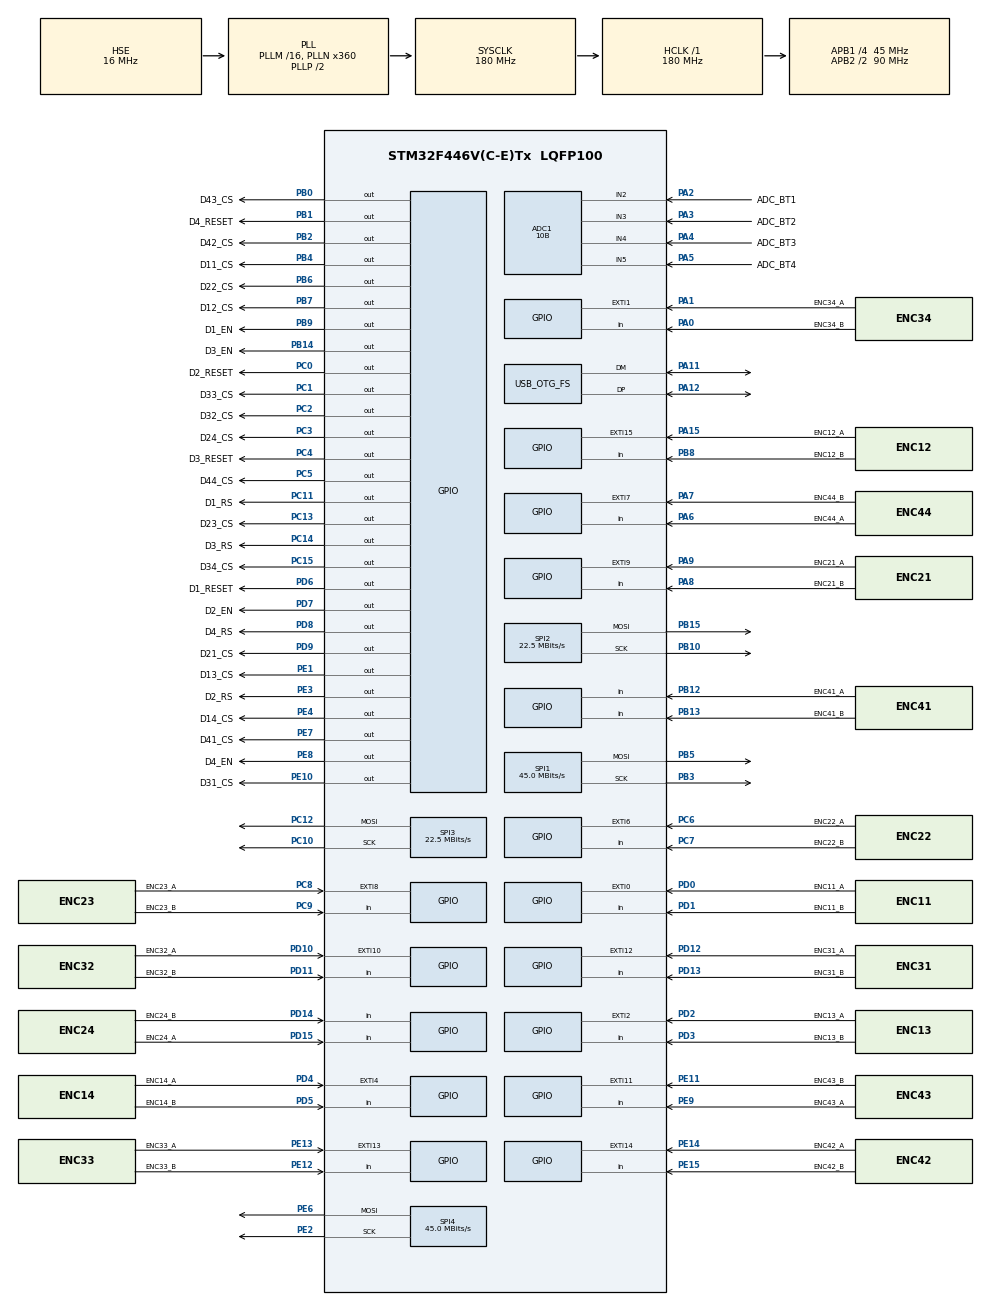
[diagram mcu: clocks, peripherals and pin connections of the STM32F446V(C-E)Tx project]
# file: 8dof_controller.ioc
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ADC1.Channel-2\#ChannelRegularConversion=ADC_CHANNEL_2
ADC1.Channel-6\#ChannelRegularConversion=ADC_CHANNEL_3
ADC1.Channel-7\#ChannelRegularConversion=ADC_CHANNEL_4
ADC1.Channel-8\#ChannelRegularConversion=ADC_CHANNEL_5
ADC1.ClockPrescaler=ADC_CLOCK_SYNC_PCLK_DIV4
ADC1.ContinuousConvMode=DISABLE
ADC1.DMAContinuousRequests=DISABLE
ADC1.DiscontinuousConvMode=DISABLE
ADC1.EOCSelection=ADC_EOC_SEQ_CONV
ADC1.ExternalTrigConv=ADC_SOFTWARE_START
ADC1.NbrOfConversion=4
ADC1.NbrOfConversionFlag=1
ADC1.Rank-2\#ChannelRegularConversion=1
ADC1.Rank-6\#ChannelRegularConversion=2
ADC1.Rank-7\#ChannelRegularConversion=3
ADC1.Rank-8\#ChannelRegularConversion=4
ADC1.Resolution=ADC_RESOLUTION_10B
ADC1.SamplingTime-2\#ChannelRegularConversion=ADC_SAMPLETIME_3CYCLES
ADC1.SamplingTime-6\#ChannelRegularConversion=ADC_SAMPLETIME_3CYCLES
ADC1.SamplingTime-7\#ChannelRegularConversion=ADC_SAMPLETIME_3CYCLES
ADC1.SamplingTime-8\#ChannelRegularConversion=ADC_SAMPLETIME_3CYCLES
ADC1.master=1
AL94.I-CUBE-USBD-COMPOSITE.1.0.3.CompositeCcUSBJjCOMPOSITEJjCDCIiACM=true
AL94.I-CUBE-USBD-COMPOSITE.1.0.3.CompositeCcUSBJjCOMPOSITEJjCOMPOSITE=true
AL94.I-CUBE-USBD-COMPOSITE.1.0.3.CompositeCcUSBJjCOMPOSITEJjCore=true
AL94.I-CUBE-USBD-COMPOSITE.1.0.3.CompositeCcUSBJjCOMPOSITEJjHIDIiCUSTOM=true
AL94.I-CUBE-USBD-COMPOSITE.1.0.3._USBD_USE_CDC_ACM=true
AL94.I-CUBE-USBD-COMPOSITE.1.0.3._USBD_USE_HID_CUSTOM=true
AL94.I-CUBE-USBD-COMPOSITE.1.0.3._USBD_USE_UAC_SPKR=false
Dma.ADC1.4.Direction=DMA_PERIPH_TO_MEMORY
Dma.ADC1.4.FIFOMode=DMA_FIFOMODE_DISABLE
Dma.ADC1.4.Instance=DMA2_Stream0
Dma.ADC1.4.MemDataAlignment=DMA_MDATAALIGN_WORD
Dma.ADC1.4.MemInc=DMA_MINC_ENABLE
Dma.ADC1.4.Mode=DMA_CIRCULAR
Dma.ADC1.4.PeriphDataAlignment=DMA_PDATAALIGN_WORD
Dma.ADC1.4.PeriphInc=DMA_PINC_DISABLE
Dma.ADC1.4.Priority=DMA_PRIORITY_LOW
Dma.Request0=SPI2_TX
Dma.Request1=SPI3_TX
Dma.Request2=SPI1_TX
Dma.Request3=SPI4_TX
Dma.Request4=ADC1
Dma.SPI1_TX.2.Direction=DMA_MEMORY_TO_PERIPH
Dma.SPI1_TX.2.FIFOMode=DMA_FIFOMODE_DISABLE
Dma.SPI1_TX.2.Instance=DMA2_Stream3
Dma.SPI1_TX.2.MemDataAlignment=DMA_MDATAALIGN_HALFWORD
Dma.SPI1_TX.2.MemInc=DMA_MINC_ENABLE
Dma.SPI1_TX.2.Mode=DMA_NORMAL
Dma.SPI1_TX.2.PeriphDataAlignment=DMA_PDATAALIGN_HALFWORD
Dma.SPI1_TX.2.PeriphInc=DMA_PINC_DISABLE
Dma.SPI1_TX.2.Priority=DMA_PRIORITY_HIGH
Dma.SPI2_TX.0.Direction=DMA_MEMORY_TO_PERIPH
Dma.SPI2_TX.0.FIFOMode=DMA_FIFOMODE_DISABLE
Dma.SPI2_TX.0.Instance=DMA1_Stream4
Dma.SPI2_TX.0.MemDataAlignment=DMA_MDATAALIGN_HALFWORD
Dma.SPI2_TX.0.MemInc=DMA_MINC_ENABLE
Dma.SPI2_TX.0.Mode=DMA_NORMAL
Dma.SPI2_TX.0.PeriphDataAlignment=DMA_PDATAALIGN_HALFWORD
Dma.SPI2_TX.0.PeriphInc=DMA_PINC_DISABLE
Dma.SPI2_TX.0.Priority=DMA_PRIORITY_HIGH
Dma.SPI3_TX.1.Direction=DMA_MEMORY_TO_PERIPH
Dma.SPI3_TX.1.FIFOMode=DMA_FIFOMODE_DISABLE
Dma.SPI3_TX.1.Instance=DMA1_Stream5
Dma.SPI3_TX.1.MemDataAlignment=DMA_MDATAALIGN_HALFWORD
Dma.SPI3_TX.1.MemInc=DMA_MINC_ENABLE
Dma.SPI3_TX.1.Mode=DMA_NORMAL
Dma.SPI3_TX.1.PeriphDataAlignment=DMA_PDATAALIGN_HALFWORD
Dma.SPI3_TX.1.PeriphInc=DMA_PINC_DISABLE
Dma.SPI3_TX.1.Priority=DMA_PRIORITY_HIGH
Dma.SPI4_TX.3.Direction=DMA_MEMORY_TO_PERIPH
Dma.SPI4_TX.3.FIFOMode=DMA_FIFOMODE_DISABLE
Dma.SPI4_TX.3.Instance=DMA2_Stream1
Dma.SPI4_TX.3.MemDataAlignment=DMA_MDATAALIGN_HALFWORD
Dma.SPI4_TX.3.MemInc=DMA_MINC_ENABLE
Dma.SPI4_TX.3.Mode=DMA_NORMAL
Dma.SPI4_TX.3.PeriphDataAlignment=DMA_PDATAALIGN_HALFWORD
Dma.SPI4_TX.3.PeriphInc=DMA_PINC_DISABLE
Dma.SPI4_TX.3.Priority=DMA_PRIORITY_HIGH
FREERTOS.Tasks01=defaultTask,0,128,StartDefaultTask,Default,NULL,Dynamic,NULL,NULL
FREERTOS.configTOTAL_HEAP_SIZE=24000
FREERTOS.configUSE_NEWLIB_REENTRANT=1
Mcu.Family=STM32F4
Mcu.Name=STM32F446V(C-E)Tx
Mcu.Package=LQFP100
NVIC.DMA1_Stream4_IRQn=true\:5\:0\:false\:false\:true\:true\:false\:true\:true
NVIC.DMA1_Stream5_IRQn=true\:5\:0\:false\:false\:true\:true\:false\:true\:true
NVIC.DMA2_Stream0_IRQn=true\:5\:0\:false\:false\:true\:true\:false\:true\:true
NVIC.DMA2_Stream1_IRQn=true\:5\:0\:false\:false\:true\:true\:false\:true\:true
NVIC.DMA2_Stream3_IRQn=true\:5\:0\:false\:false\:true\:true\:false\:true\:true
NVIC.EXTI0_IRQn=true\:5\:0\:false\:false\:true\:true\:true\:true\:true
NVIC.EXTI15_10_IRQn=true\:5\:0\:false\:false\:true\:true\:true\:true\:true
NVIC.EXTI1_IRQn=true\:5\:0\:false\:false\:true\:true\:true\:true\:true
NVIC.EXTI2_IRQn=true\:5\:0\:false\:false\:true\:true\:true\:true\:true
NVIC.EXTI4_IRQn=true\:5\:0\:false\:false\:true\:true\:true\:true\:true
NVIC.EXTI9_5_IRQn=true\:5\:0\:false\:false\:true\:true\:true\:true\:true
NVIC.OTG_FS_IRQn=true\:5\:0\:false\:false\:true\:true\:true\:true\:true
NVIC.PriorityGroup=NVIC_PRIORITYGROUP_4
NVIC.SPI1_IRQn=true\:5\:0\:false\:false\:true\:true\:true\:true\:true
NVIC.SPI2_IRQn=true\:5\:0\:false\:false\:true\:true\:true\:true\:true
NVIC.SPI3_IRQn=true\:5\:0\:false\:false\:true\:true\:true\:true\:true
NVIC.SPI4_IRQn=true\:5\:0\:false\:false\:true\:true\:true\:true\:true
NVIC.TIM2_IRQn=true\:15\:0\:false\:false\:true\:false\:false\:true\:true
NVIC.TIM3_IRQn=true\:5\:0\:false\:false\:true\:true\:true\:true\:true
NVIC.TIM6_DAC_IRQn=true\:5\:0\:false\:false\:true\:true\:true\:true\:true
NVIC.TimeBase=TIM2_IRQn
NVIC.TimeBaseIP=TIM2
PA0-WKUP.GPIO_Label=ENC34_B
PA0-WKUP.Signal=GPIO_Input
PA1.GPIO_Label=ENC34_A
PA1.GPIO_ModeDefaultEXTI=GPIO_MODE_IT_RISING_FALLING
PA1.Signal=GPXTI1
PA11.Mode=Device_Only
PA11.Signal=USB_OTG_FS_DM
PA12.Mode=Device_Only
PA12.Signal=USB_OTG_FS_DP
PA13.Mode=Serial_Wire
PA13.Signal=SYS_JTMS-SWDIO
PA14.Mode=Serial_Wire
PA14.Signal=SYS_JTCK-SWCLK
PA15.GPIO_Label=ENC12_A
PA15.GPIO_ModeDefaultEXTI=GPIO_MODE_IT_RISING_FALLING
PA15.Signal=GPXTI15
PA2.GPIO_Label=ADC_BT1
PA2.Signal=ADCx_IN2
PA3.GPIO_Label=ADC_BT2
PA3.Signal=ADCx_IN3
PA4.GPIO_Label=ADC_BT3
PA4.Signal=ADCx_IN4
PA5.GPIO_Label=ADC_BT4
PA5.Signal=ADCx_IN5
PA6.GPIO_Label=ENC44_A
PA6.Signal=GPIO_Input
PA7.GPIO_Label=ENC44_B
PA7.GPIO_ModeDefaultEXTI=GPIO_MODE_IT_RISING_FALLING
PA7.Signal=GPXTI7
PA8.GPIO_Label=ENC21_B
PA8.Signal=GPIO_Input
PA9.GPIO_Label=ENC21_A
PA9.GPIO_ModeDefaultEXTI=GPIO_MODE_IT_RISING_FALLING
PA9.Signal=GPXTI9
PB0.GPIO_Label=D43_CS
PB0.GPIO_Speed=GPIO_SPEED_FREQ_VERY_HIGH
PB0.PinState=GPIO_PIN_SET
PB0.Signal=GPIO_Output
PB1.GPIO_Label=D4_RESET
PB1.GPIO_PuPd=GPIO_PULLUP
PB1.PinState=GPIO_PIN_SET
PB1.Signal=GPIO_Output
PB10.GPIO_PuPd=GPIO_PULLDOWN
PB10.Mode=TX_Only_Simplex_Unidirect_Master
PB10.Signal=SPI2_SCK
PB12.GPIO_Label=ENC41_A
PB12.Signal=GPIO_Input
PB13.GPIO_Label=ENC41_B
PB13.Signal=GPIO_Input
PB14.GPIO_Label=D3_EN
PB14.PinState=GPIO_PIN_RESET
PB14.Signal=GPIO_Output
PB15.GPIO_PuPd=GPIO_PULLUP
PB15.Mode=TX_Only_Simplex_Unidirect_Master
PB15.Signal=SPI2_MOSI
PB2.GPIO_Label=D42_CS
PB2.PinState=GPIO_PIN_SET
PB2.Signal=GPIO_Output
PB3.GPIO_PuPd=GPIO_PULLDOWN
PB3.Mode=TX_Only_Simplex_Unidirect_Master
PB3.Signal=SPI1_SCK
PB4.GPIO_Label=D11_CS
PB4.GPIO_Speed=GPIO_SPEED_FREQ_VERY_HIGH
PB4.PinState=GPIO_PIN_SET
PB4.Signal=GPIO_Output
PB5.GPIO_PuPd=GPIO_PULLUP
PB5.Mode=TX_Only_Simplex_Unidirect_Master
PB5.Signal=SPI1_MOSI
PB6.GPIO_Label=D22_CS
PB6.GPIO_Speed=GPIO_SPEED_FREQ_VERY_HIGH
PB6.PinState=GPIO_PIN_SET
PB6.Signal=GPIO_Output
PB7.GPIO_Label=D12_CS
PB7.GPIO_Speed=GPIO_SPEED_FREQ_VERY_HIGH
PB7.PinState=GPIO_PIN_SET
PB7.Signal=GPIO_Output
PB8.GPIO_Label=ENC12_B
PB8.Signal=GPIO_Input
PB9.GPIO_Label=D1_EN
PB9.GPIO_PuPd=GPIO_NOPULL
PB9.PinState=GPIO_PIN_RESET
PB9.Signal=GPIO_Output
PC0.GPIO_Label=D2_RESET
PC0.GPIO_PuPd=GPIO_PULLUP
PC0.PinState=GPIO_PIN_SET
PC0.Signal=GPIO_Output
PC1.GPIO_Label=D33_CS
PC1.GPIO_Speed=GPIO_SPEED_FREQ_VERY_HIGH
PC1.PinState=GPIO_PIN_SET
PC1.Signal=GPIO_Output
PC10.GPIO_PuPd=GPIO_PULLDOWN
PC10.Mode=TX_Only_Simplex_Unidirect_Master
PC10.Signal=SPI3_SCK
PC11.GPIO_Label=D1_RS
PC11.GPIO_Speed=GPIO_SPEED_FREQ_VERY_HIGH
PC11.PinState=GPIO_PIN_SET
PC11.Signal=GPIO_Output
PC12.GPIO_PuPd=GPIO_PULLUP
PC12.Mode=TX_Only_Simplex_Unidirect_Master
PC12.Signal=SPI3_MOSI
PC13.GPIO_Label=D23_CS
PC13.GPIO_Speed=GPIO_SPEED_FREQ_LOW
PC13.PinState=GPIO_PIN_SET
PC13.Signal=GPIO_Output
PC14-OSC32_IN.GPIO_Label=D3_RS
PC14-OSC32_IN.PinState=GPIO_PIN_SET
PC14-OSC32_IN.Signal=GPIO_Output
PC15-OSC32_OUT.GPIO_Label=D34_CS
PC15-OSC32_OUT.PinState=GPIO_PIN_SET
PC15-OSC32_OUT.Signal=GPIO_Output
PC2.GPIO_Label=D32_CS
PC2.GPIO_Speed=GPIO_SPEED_FREQ_VERY_HIGH
PC2.PinState=GPIO_PIN_SET
PC2.Signal=GPIO_Output
PC3.GPIO_Label=D24_CS
PC3.GPIO_Speed=GPIO_SPEED_FREQ_VERY_HIGH
PC3.PinState=GPIO_PIN_SET
PC3.Signal=GPIO_Output
PC4.GPIO_Label=D3_RESET
PC4.GPIO_PuPd=GPIO_PULLUP
PC4.PinState=GPIO_PIN_SET
PC4.Signal=GPIO_Output
PC5.GPIO_Label=D44_CS
PC5.GPIO_Speed=GPIO_SPEED_FREQ_VERY_HIGH
PC5.PinState=GPIO_PIN_SET
PC5.Signal=GPIO_Output
PC6.GPIO_Label=ENC22_A
PC6.GPIO_ModeDefaultEXTI=GPIO_MODE_IT_RISING_FALLING
PC6.Signal=GPXTI6
PC7.GPIO_Label=ENC22_B
PC7.Signal=GPIO_Input
PC8.GPIO_Label=ENC23_A
PC8.GPIO_ModeDefaultEXTI=GPIO_MODE_IT_RISING_FALLING
PC8.Signal=GPXTI8
PC9.GPIO_Label=ENC23_B
PC9.Signal=GPIO_Input
PD0.GPIO_Label=ENC11_A
PD0.GPIO_ModeDefaultEXTI=GPIO_MODE_IT_RISING_FALLING
PD0.GPIO_PuPd=GPIO_NOPULL
PD0.Signal=GPXTI0
PD1.GPIO_Label=ENC11_B
PD1.GPIO_PuPd=GPIO_NOPULL
PD1.Signal=GPIO_Input
PD10.GPIO_Label=ENC32_A
PD10.GPIO_ModeDefaultEXTI=GPIO_MODE_IT_RISING_FALLING
PD10.Signal=GPXTI10
PD11.GPIO_Label=ENC32_B
PD11.Signal=GPIO_Input
PD12.GPIO_Label=ENC31_A
PD12.GPIO_ModeDefaultEXTI=GPIO_MODE_IT_RISING_FALLING
PD12.Signal=GPXTI12
PD13.GPIO_Label=ENC31_B
PD13.Signal=GPIO_Input
PD14.GPIO_Label=ENC24_B
PD14.Signal=GPIO_Input
PD15.GPIO_Label=ENC24_A
PD15.Signal=GPIO_Input
PD2.GPIO_Label=ENC13_A
PD2.GPIO_ModeDefaultEXTI=GPIO_MODE_IT_RISING_FALLING
PD2.Signal=GPXTI2
PD3.GPIO_Label=ENC13_B
PD3.Signal=GPIO_Input
PD4.GPIO_Label=ENC14_A
PD4.GPIO_ModeDefaultEXTI=GPIO_MODE_IT_RISING_FALLING
PD4.Signal=GPXTI4
PD5.GPIO_Label=ENC14_B
PD5.Signal=GPIO_Input
PD6.GPIO_Label=D1_RESET
PD6.GPIO_PuPd=GPIO_PULLUP
PD6.PinState=GPIO_PIN_SET
PD6.Signal=GPIO_Output
PD7.GPIO_Label=D2_EN
PD7.Signal=GPIO_Output
PD8.GPIO_Label=D4_RS
PD8.GPIO_Speed=GPIO_SPEED_FREQ_VERY_HIGH
PD8.PinState=GPIO_PIN_SET
PD8.Signal=GPIO_Output
PD9.GPIO_Label=D21_CS
PD9.GPIO_Speed=GPIO_SPEED_FREQ_VERY_HIGH
PD9.PinState=GPIO_PIN_SET
PD9.Signal=GPIO_Output
PE1.GPIO_Label=D13_CS
PE1.GPIO_Speed=GPIO_SPEED_FREQ_VERY_HIGH
PE1.PinState=GPIO_PIN_SET
PE1.Signal=GPIO_Output
PE10.GPIO_Label=D31_CS
PE10.GPIO_Speed=GPIO_SPEED_FREQ_VERY_HIGH
PE10.PinState=GPIO_PIN_SET
PE10.Signal=GPIO_Output
PE11.GPIO_Label=ENC43_B
PE11.GPIO_ModeDefaultEXTI=GPIO_MODE_IT_RISING_FALLING
PE11.Signal=GPXTI11
PE12.GPIO_Label=ENC33_B
PE12.Signal=GPIO_Input
PE13.GPIO_Label=ENC33_A
PE13.GPIO_ModeDefaultEXTI=GPIO_MODE_IT_RISING_FALLING
PE13.Signal=GPXTI13
PE14.GPIO_Label=ENC42_A
PE14.GPIO_ModeDefaultEXTI=GPIO_MODE_IT_RISING_FALLING
PE14.Signal=GPXTI14
PE15.GPIO_Label=ENC42_B
PE15.Signal=GPIO_Input
PE2.GPIO_PuPd=GPIO_PULLDOWN
PE2.Mode=TX_Only_Simplex_Unidirect_Master
PE2.Signal=SPI4_SCK
PE3.GPIO_Label=D2_RS
PE3.GPIO_Speed=GPIO_SPEED_FREQ_VERY_HIGH
PE3.PinState=GPIO_PIN_SET
PE3.Signal=GPIO_Output
PE4.GPIO_Label=D14_CS
PE4.GPIO_Speed=GPIO_SPEED_FREQ_VERY_HIGH
PE4.PinState=GPIO_PIN_SET
PE4.Signal=GPIO_Output
PE6.GPIO_PuPd=GPIO_PULLUP
PE6.Mode=TX_Only_Simplex_Unidirect_Master
PE6.Signal=SPI4_MOSI
PE7.GPIO_Label=D41_CS
PE7.GPIO_Speed=GPIO_SPEED_FREQ_VERY_HIGH
PE7.PinState=GPIO_PIN_SET
PE7.Signal=GPIO_Output
PE8.GPIO_Label=D4_EN
PE8.Signal=GPIO_Output
PE9.GPIO_Label=ENC43_A
PE9.Signal=GPIO_Input
PH0-OSC_IN.Mode=HSE-External-Oscillator
PH0-OSC_IN.Signal=RCC_OSC_IN
PH1-OSC_OUT.Mode=HSE-External-Oscillator
PH1-OSC_OUT.Signal=RCC_OSC_OUT
ProjectManager.HeapSize=0x200
ProjectManager.StackSize=0x400
ProjectManager.TargetToolchain=STM32CubeIDE
RCC.AHBFreq_Value=180000000
RCC.APB1CLKDivider=RCC_HCLK_DIV4
RCC.APB1Freq_Value=45000000
RCC.APB1TimFreq_Value=90000000
RCC.APB2CLKDivider=RCC_HCLK_DIV2
RCC.APB2Freq_Value=90000000
RCC.APB2TimFreq_Value=180000000
RCC.CortexFreq_Value=180000000
RCC.HCLKFreq_Value=180000000
RCC.HSE_VALUE=16000000
RCC.PLLN=360
RCC.PLLQ=8
RCC.PLLSAIP=RCC_PLLSAIP_DIV4
RCC.SYSCLKFreq_VALUE=180000000
RCC.SYSCLKSource=RCC_SYSCLKSOURCE_PLLCLK
RCC.USBCLockSelection=RCC_CLK48CLKSOURCE_PLLSAIP
RCC.USBFreq_Value=48000000
RCC.VCOOutputFreq_Value=360000000
SH.ADCx_IN2.0=ADC1_IN2,IN2
SH.ADCx_IN3.0=ADC1_IN3,IN3
SH.ADCx_IN4.0=ADC1_IN4,IN4
SH.ADCx_IN5.0=ADC1_IN5,IN5
SPI1.BaudRatePrescaler=SPI_BAUDRATEPRESCALER_2
SPI1.CalculateBaudRate=45.0 MBits/s
SPI1.Direction=SPI_DIRECTION_2LINES
SPI1.FirstBit=SPI_FIRSTBIT_MSB
SPI1.Mode=SPI_MODE_MASTER
SPI1.VirtualType=VM_MASTER
SPI2.BaudRatePrescaler=SPI_BAUDRATEPRESCALER_2
SPI2.CalculateBaudRate=22.5 MBits/s
SPI2.Direction=SPI_DIRECTION_2LINES
SPI2.Mode=SPI_MODE_MASTER
SPI2.VirtualType=VM_MASTER
SPI3.BaudRatePrescaler=SPI_BAUDRATEPRESCALER_2
SPI3.CalculateBaudRate=22.5 MBits/s
SPI3.Direction=SPI_DIRECTION_2LINES
SPI3.Mode=SPI_MODE_MASTER
SPI3.VirtualType=VM_MASTER
SPI4.BaudRatePrescaler=SPI_BAUDRATEPRESCALER_2
SPI4.CalculateBaudRate=45.0 MBits/s
SPI4.Direction=SPI_DIRECTION_2LINES
SPI4.Mode=SPI_MODE_MASTER
SPI4.VirtualType=VM_MASTER
TIM3.AutoReloadPreload=TIM_AUTORELOAD_PRELOAD_ENABLE
TIM3.Period=9000-1
TIM3.Prescaler=10-1
TIM3.TIM_MasterOutputTrigger=TIM_TRGO_UPDATE
TIM6.AutoReloadPreload=TIM_AUTORELOAD_PRELOAD_ENABLE
TIM6.Period=8999
TIM6.Prescaler=0
TIM6.TIM_MasterOutputTrigger=TIM_TRGO_RESET
USB_OTG_FS.VirtualMode=Device_Only
VP_AL94.I-CUBE-USBD-COMPOSITE_VS_USBJjComposite_1.0.0_1.0.3.Mode=USBJjComposite
VP_FREERTOS_VS_CMSIS_V1.Mode=CMSIS_V1
VP_SYS_VS_tim2.Mode=TIM2
VP_TIM3_VS_ClockSourceINT.Mode=Internal
VP_TIM6_VS_ClockSourceINT.Mode=Enable_Timer
board=custom

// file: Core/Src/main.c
/* USER CODE BEGIN Header */
/**
 ******************************************************************************
 * @file           : main.c
 * @brief          : Main program body
 ******************************************************************************
 * @attention
 *
 * Copyright (c) 2024 STMicroelectronics.
 * All rights reserved.
 *
 * This software is licensed under terms that can be found in the LICENSE file
 * in the root directory of this software component.
 * If no LICENSE file comes with this software, it is provided AS-IS.
 *
 ******************************************************************************
 */
/* USER CODE END Header */
#include "main.h"
#include "cmsis_os.h"
#include "adc.h"
#include "dma.h"
#include "spi.h"
#include "tim.h"
#include "usb_otg.h"
#include "gpio.h"

/* USER CODE BEGIN Includes */
#include "task_buttons.h"
#include "task_encoder.h"
#include "task_lvgl.h"
#include "task_midi.h"
/* USER CODE END Includes */

/* USER CODE BEGIN PV */
uint32_t value_adc[4];
/* USER CODE END PV */

void SystemClock_Config(void);
void MX_FREERTOS_Init(void);

int main(void)
{

  /* MCU Configuration--------------------------------------------------------*/

  /* Reset of all peripherals, Initializes the Flash interface and the Systick. */
  HAL_Init();

  /* Configure the system clock */
  SystemClock_Config();

  /* Initialize all configured peripherals */
  MX_GPIO_Init();
  MX_DMA_Init();
  MX_ADC1_Init();
  MX_SPI1_Init();
  MX_SPI2_Init();
  MX_SPI3_Init();
  MX_SPI4_Init();
  MX_TIM6_Init();
  MX_TIM3_Init();
  MX_USB_OTG_FS_PCD_Init();
  /* USER CODE BEGIN 2 */
  HAL_TIM_Base_Start_IT(&htim6);

//  MX_USB_DEVICE_Init();
  HAL_TIM_Base_Start(&htim3);
  /* USER CODE END 2 */

  /* Call init function for freertos objects (in freertos.c) */
  MX_FREERTOS_Init();

  /* Start scheduler */
  osKernelStart();

  /* We should never get here as control is now taken by the scheduler */
  /* Infinite loop */
	while (1) {

	}
}

void SystemClock_Config(void)
{
  RCC_OscInitTypeDef RCC_OscInitStruct = {0};
  RCC_ClkInitTypeDef RCC_ClkInitStruct = {0};

  /** Configure the main internal regulator output voltage
  */
  __HAL_RCC_PWR_CLK_ENABLE();
  __HAL_PWR_VOLTAGESCALING_CONFIG(PWR_REGULATOR_VOLTAGE_SCALE1);

  /** Initializes the RCC Oscillators according to the specified parameters
  * in the RCC_OscInitTypeDef structure.
  */
  RCC_OscInitStruct.OscillatorType = RCC_OSCILLATORTYPE_HSE;
  RCC_OscInitStruct.HSEState = RCC_HSE_ON;
  RCC_OscInitStruct.PLL.PLLState = RCC_PLL_ON;
  RCC_OscInitStruct.PLL.PLLSource = RCC_PLLSOURCE_HSE;
  RCC_OscInitStruct.PLL.PLLM = 16;
  RCC_OscInitStruct.PLL.PLLN = 360;
  RCC_OscInitStruct.PLL.PLLP = RCC_PLLP_DIV2;
  RCC_OscInitStruct.PLL.PLLQ = 8;
  RCC_OscInitStruct.PLL.PLLR = 2;
  if (HAL_RCC_OscConfig(&RCC_OscInitStruct) != HAL_OK)
  {
    Error_Handler();
  }

  /** Activate the Over-Drive mode
  */
  if (HAL_PWREx_EnableOverDrive() != HAL_OK)
  {
    Error_Handler();
  }

  /** Initializes the CPU, AHB and APB buses clocks
  */
  RCC_ClkInitStruct.ClockType = RCC_CLOCKTYPE_HCLK|RCC_CLOCKTYPE_SYSCLK
                              |RCC_CLOCKTYPE_PCLK1|RCC_CLOCKTYPE_PCLK2;
  RCC_ClkInitStruct.SYSCLKSource = RCC_SYSCLKSOURCE_PLLCLK;
  RCC_ClkInitStruct.AHBCLKDivider = RCC_SYSCLK_DIV1;
  RCC_ClkInitStruct.APB1CLKDivider = RCC_HCLK_DIV4;
  RCC_ClkInitStruct.APB2CLKDivider = RCC_HCLK_DIV2;

  if (HAL_RCC_ClockConfig(&RCC_ClkInitStruct, FLASH_LATENCY_5) != HAL_OK)
  {
    Error_Handler();
  }
}

void HAL_TIM_PeriodElapsedCallback(TIM_HandleTypeDef *htim)
{
  if (htim->Instance == TIM2) {
    HAL_IncTick();
  }
}

void Error_Handler(void)
{
	__disable_irq();
	while (1) {
	}
}

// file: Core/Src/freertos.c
/* USER CODE BEGIN Header */
/**
  ******************************************************************************
  * File Name          : freertos.c
  * Description        : Code for freertos applications
  ******************************************************************************
  * @attention
  *
  * Copyright (c) 2024 STMicroelectronics.
  * All rights reserved.
  *
  * This software is licensed under terms that can be found in the LICENSE file
  * in the root directory of this software component.
  * If no LICENSE file comes with this software, it is provided AS-IS.
  *
  ******************************************************************************
  */
/* USER CODE END Header */

#include "FreeRTOS.h"
#include "task.h"
#include "main.h"
#include "cmsis_os.h"

/* USER CODE BEGIN Includes */
// #include "task_buttons.h"
// #include "task_encoder.h"
// #include "task_lvgl.h"
// #include "task_midi.h"
// #include "task_acm.h"
/* USER CODE END Includes */

osThreadId defaultTaskHandle;

void StartDefaultTask(void const * argument);

// void MX_FREERTOS_Init(void); /* (MISRA C 2004 rule 8.1) */

/* GetIdleTaskMemory prototype (linked to static allocation support) */
void vApplicationGetIdleTaskMemory( StaticTask_t **ppxIdleTaskTCBBuffer, StackType_t **ppxIdleTaskStackBuffer, uint32_t *pulIdleTaskStackSize );

/* USER CODE BEGIN GET_IDLE_TASK_MEMORY */
static StaticTask_t xIdleTaskTCBBuffer;
static StackType_t xIdleStack[configMINIMAL_STACK_SIZE];

void vApplicationGetIdleTaskMemory( StaticTask_t **ppxIdleTaskTCBBuffer, StackType_t **ppxIdleTaskStackBuffer, uint32_t *pulIdleTaskStackSize )
{
  *ppxIdleTaskTCBBuffer = &xIdleTaskTCBBuffer;
  *ppxIdleTaskStackBuffer = &xIdleStack[0];
  *pulIdleTaskStackSize = configMINIMAL_STACK_SIZE;
  /* place for user code */
}
/* USER CODE END GET_IDLE_TASK_MEMORY */

void MX_FREERTOS_Init(void) {

  /* Create the thread(s) */
  /* definition and creation of defaultTask */
//  osThreadDef(defaultTask, StartDefaultTask, osPriorityNormal, 0, 128);
//  defaultTaskHandle = osThreadCreate(osThread(defaultTask), NULL);

  /* USER CODE BEGIN RTOS_THREADS */
	// TaskLVGL_createTask();
	// TaskMIDI_createTask();
	// TaskButtons_createTask();
	// TaskEncoder_createTask();

 	// TaskACM_createTask();
  /* add threads, ... */
  /* USER CODE END RTOS_THREADS */

}

void StartDefaultTask(void const * argument)
{
  for(;;)
  {
    osDelay(1);
  }
}
